# TM4C1237H6PGE register map
Vendor: Texas Instruments; Series: TM4C; File version: 12591
CPU: CM4 r1p2, little endian, MPU, FPU, 3 interrupt priority bits
Registers are 32-bit, read-write, no defined reset value unless marked. A register's access mark holds for its fields unless they carry their own. Offsets are from the block's base; [hi:lo] are bit positions; {n}, {i} and the like mark numbered series.

## HIB — Register map for HIB peripheral
Base 0x400FC000; register names take the prefix HIB
0x00 RTCC — Hibernation RTC Counter
  [31:0] HIB_RTCC — RTC Counter
0x04 RTCM0 — Hibernation RTC Match 0
  [31:0] HIB_RTCM0 — RTC Match 0
0x0C RTCLD — Hibernation RTC Load
  [31:0] HIB_RTCLD — RTC Load
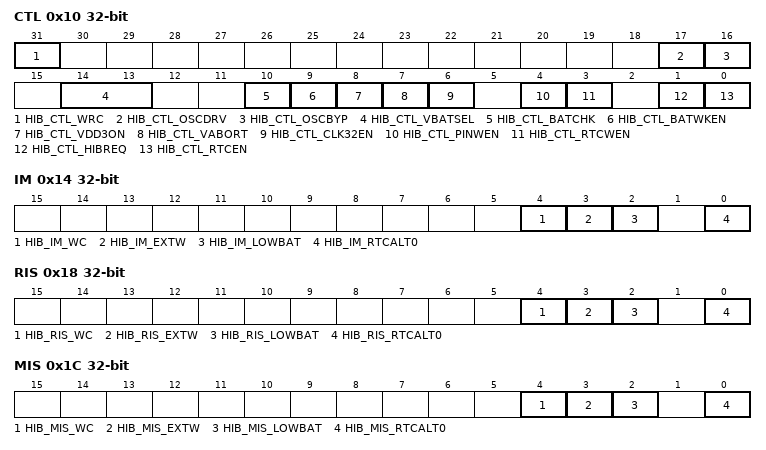
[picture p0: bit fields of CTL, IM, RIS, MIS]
0x10 CTL — Hibernation Control
  [31] HIB_CTL_WRC — Write Complete/Capable
  [17] HIB_CTL_OSCDRV — Oscillator Drive Capability
  [16] HIB_CTL_OSCBYP — Oscillator Bypass
  [14:13] HIB_CTL_VBATSEL — Select for Low-Battery Comparator
    0=HIB_CTL_VBATSEL_1_9V (1.9 Volts); 1=HIB_CTL_VBATSEL_2_1V (2.1 Volts (default)); 2=HIB_CTL_VBATSEL_2_3V (2.3 Volts); 3=HIB_CTL_VBATSEL_2_5V (2.5 Volts)
  [10] HIB_CTL_BATCHK — Check Battery Status
  [9] HIB_CTL_BATWKEN — Wake on Low Battery
  [8] HIB_CTL_VDD3ON — VDD Powered
  [7] HIB_CTL_VABORT — Power Cut Abort Enable
  [6] HIB_CTL_CLK32EN — Clocking Enable
  [4] HIB_CTL_PINWEN — External Wake Pin Enable
  [3] HIB_CTL_RTCWEN — RTC Wake-up Enable
  [1] HIB_CTL_HIBREQ — Hibernation Request
  [0] HIB_CTL_RTCEN — RTC Timer Enable
0x14 IM — Hibernation Interrupt Mask
  [4] HIB_IM_WC — External Write Complete/Capable Interrupt Mask
  [3] HIB_IM_EXTW — External Wake-Up Interrupt Mask
  [2] HIB_IM_LOWBAT — Low Battery Voltage Interrupt Mask
  [0] HIB_IM_RTCALT0 — RTC Alert 0 Interrupt Mask
0x18 RIS — Hibernation Raw Interrupt Status
  [4] HIB_RIS_WC — Write Complete/Capable Raw Interrupt Status
  [3] HIB_RIS_EXTW — External Wake-Up Raw Interrupt Status
  [2] HIB_RIS_LOWBAT — Low Battery Voltage Raw Interrupt Status
  [0] HIB_RIS_RTCALT0 — RTC Alert 0 Raw Interrupt Status
0x1C MIS — Hibernation Masked Interrupt Status
  [4] HIB_MIS_WC — Write Complete/Capable Masked Interrupt Status
  [3] HIB_MIS_EXTW — External Wake-Up Masked Interrupt Status
  [2] HIB_MIS_LOWBAT — Low Battery Voltage Masked Interrupt Status
  [0] HIB_MIS_RTCALT0 — RTC Alert 0 Masked Interrupt Status
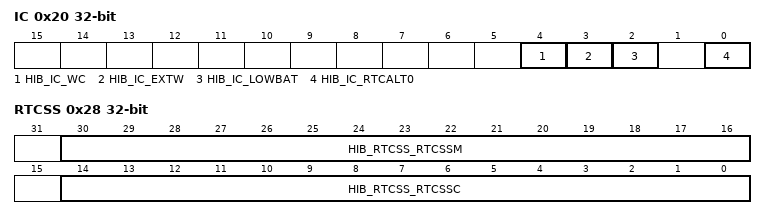
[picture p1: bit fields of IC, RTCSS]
0x20 IC — Hibernation Interrupt Clear
  [4] HIB_IC_WC — Write Complete/Capable Interrupt Clear
  [3] HIB_IC_EXTW — External Wake-Up Interrupt Clear
  [2] HIB_IC_LOWBAT — Low Battery Voltage Interrupt Clear
  [0] HIB_IC_RTCALT0 — RTC Alert0 Masked Interrupt Clear
0x24 RTCT — Hibernation RTC Trim
  [15:0] HIB_RTCT_TRIM — RTC Trim Value
0x28 RTCSS — Hibernation RTC Sub Seconds
  [30:16] HIB_RTCSS_RTCSSM — RTC Sub Seconds Match
  [14:0] HIB_RTCSS_RTCSSC — RTC Sub Seconds Count
0x30 DATA — Hibernation Data
  [31:0] HIB_DATA_RTD — Hibernation Module NV Data

## FLASH_CTRL — Register map for FLASH_CTRL peripheral
Base 0x400FD000; register names take the prefix FLASH_CTRL
0x00 FMA — Flash Memory Address
  [17:0] FLASH_FMA_OFFSET — Address Offset
0x04 FMD — Flash Memory Data
  [31:0] FLASH_FMD_DATA — Data Value
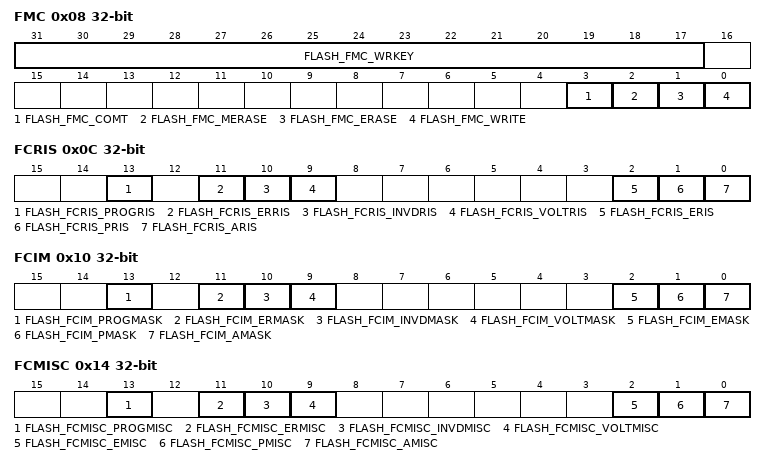
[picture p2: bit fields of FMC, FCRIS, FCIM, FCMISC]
0x08 FMC — Flash Memory Control
  [31:17] FLASH_FMC_WRKEY — FLASH write key
  [3] FLASH_FMC_COMT — Commit Register Value
  [2] FLASH_FMC_MERASE — Mass Erase Flash Memory
  [1] FLASH_FMC_ERASE — Erase a Page of Flash Memory
  [0] FLASH_FMC_WRITE — Write a Word into Flash Memory
0x0C FCRIS — Flash Controller Raw Interrupt Status
  [13] FLASH_FCRIS_PROGRIS — Program Verify Error Raw Interrupt Status
  [11] FLASH_FCRIS_ERRIS — Erase Verify Error Raw Interrupt Status
  [10] FLASH_FCRIS_INVDRIS — Invalid Data Raw Interrupt Status
  [9] FLASH_FCRIS_VOLTRIS — Pump Voltage Raw Interrupt Status
  [2] FLASH_FCRIS_ERIS — EEPROM Raw Interrupt Status
  [1] FLASH_FCRIS_PRIS — Programming Raw Interrupt Status
  [0] FLASH_FCRIS_ARIS — Access Raw Interrupt Status
0x10 FCIM — Flash Controller Interrupt Mask
  [13] FLASH_FCIM_PROGMASK — PROGVER Interrupt Mask
  [11] FLASH_FCIM_ERMASK — ERVER Interrupt Mask
  [10] FLASH_FCIM_INVDMASK — Invalid Data Interrupt Mask
  [9] FLASH_FCIM_VOLTMASK — VOLT Interrupt Mask
  [2] FLASH_FCIM_EMASK — EEPROM Interrupt Mask
  [1] FLASH_FCIM_PMASK — Programming Interrupt Mask
  [0] FLASH_FCIM_AMASK — Access Interrupt Mask
0x14 FCMISC — Flash Controller Masked Interrupt Status and Clear
  [13] FLASH_FCMISC_PROGMISC — PROGVER Masked Interrupt Status and Clear
  [11] FLASH_FCMISC_ERMISC — ERVER Masked Interrupt Status and Clear
  [10] FLASH_FCMISC_INVDMISC — Invalid Data Masked Interrupt Status and Clear
  [9] FLASH_FCMISC_VOLTMISC — VOLT Masked Interrupt Status and Clear
  [2] FLASH_FCMISC_EMISC — EEPROM Masked Interrupt Status and Clear
  [1] FLASH_FCMISC_PMISC — Programming Masked Interrupt Status and Clear
  [0] FLASH_FCMISC_AMISC — Access Masked Interrupt Status and Clear
0x20 FMC2 — Flash Memory Control 2
  [0] FLASH_FMC2_WRBUF — Buffered Flash Memory Write
0x30 FWBVAL — Flash Write Buffer Valid
  [31:0] FLASH_FWBVAL_FWB — Flash Memory Write Buffer
0x100 FWBN — Flash Write Buffer n
  [31:0] FLASH_FWBN_DATA — Data
0xFC0 FSIZE — Flash Size
  [15:0] FLASH_FSIZE_SIZE
    127=FLASH_FSIZE_SIZE_256KB (256 KB of Flash)
0xFC4 SSIZE — SRAM Size
  [15:0] FLASH_SSIZE_SIZE
    127=FLASH_SSIZE_SIZE_32KB (32 KB of SRAM)
0xFCC ROMSWMAP — ROM Software Map
0xFCC ROMSWMAP (FLASH_CTRL_ALT view) — ROM Software Map
  [0] FLASH_ROMSWMAP_SAFERTOS — SafeRTOS Present
0x10F0 RMCTL — ROM Control
  [0] FLASH_RMCTL_BA — Boot Alias
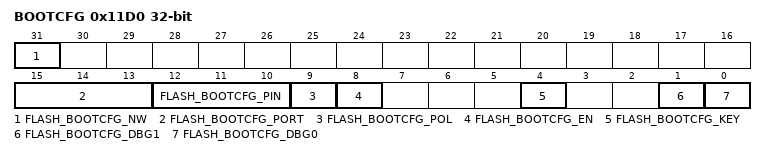
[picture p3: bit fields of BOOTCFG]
0x11D0 BOOTCFG — Boot Configuration
  [31] FLASH_BOOTCFG_NW — Not Written
  [15:13] FLASH_BOOTCFG_PORT — Boot GPIO Port
    0=FLASH_BOOTCFG_PORT_A (Port A); 1=FLASH_BOOTCFG_PORT_B (Port B); 2=FLASH_BOOTCFG_PORT_C (Port C); 3=FLASH_BOOTCFG_PORT_D (Port D); 4=FLASH_BOOTCFG_PORT_E (Port E); 5=FLASH_BOOTCFG_PORT_F (Port F); 6=FLASH_BOOTCFG_PORT_G (Port G); 7=FLASH_BOOTCFG_PORT_H (Port H)
  [12:10] FLASH_BOOTCFG_PIN — Boot GPIO Pin
    {v}=Pin {v} (v=0..7)
  [9] FLASH_BOOTCFG_POL — Boot GPIO Polarity
  [8] FLASH_BOOTCFG_EN — Boot GPIO Enable
  [4] FLASH_BOOTCFG_KEY — KEY Select
  [1] FLASH_BOOTCFG_DBG1 — Debug Control 1
  [0] FLASH_BOOTCFG_DBG0 — Debug Control 0
{0x11E0+4i} USERREG{i} (i=0..3) — User Register {i}
  [31:0] FLASH_USERREG{i}_DATA — User Data
{0x1200+4i} FMPRE{i} (i=0..3) — Flash Memory Protection Read Enable {i}
{0x1400+4i} FMPPE{i} (i=0..3) — Flash Memory Protection Program Enable {i}

## UDMA — Register map for UDMA peripheral
Base 0x400FF000; register names take the prefix UDMA
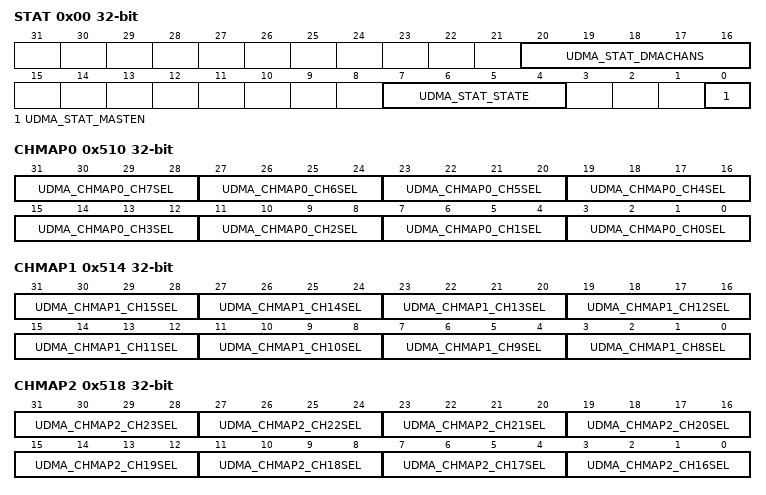
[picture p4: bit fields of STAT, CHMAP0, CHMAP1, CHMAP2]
0x00 STAT — DMA Status
  [20:16] UDMA_STAT_DMACHANS — Available uDMA Channels Minus 1
  [7:4] UDMA_STAT_STATE — Control State Machine Status
    0=UDMA_STAT_STATE_IDLE (Idle); 1=UDMA_STAT_STATE_RD_CTRL (Reading channel controller data); 2=UDMA_STAT_STATE_RD_SRCENDP (Reading source end pointer); 3=UDMA_STAT_STATE_RD_DSTENDP (Reading destination end pointer); 4=UDMA_STAT_STATE_RD_SRCDAT (Reading source data); 5=UDMA_STAT_STATE_WR_DSTDAT (Writing destination data); 6=UDMA_STAT_STATE_WAIT (Waiting for uDMA request to clear); 7=UDMA_STAT_STATE_WR_CTRL (Writing channel controller data); 8=UDMA_STAT_STATE_STALL (Stalled); 9=UDMA_STAT_STATE_DONE (Done); 10=UDMA_STAT_STATE_UNDEF (Undefined)
  [0] UDMA_STAT_MASTEN — Master Enable Status
0x04 CFG wo — DMA Configuration
  [0] UDMA_CFG_MASTEN — Controller Master Enable
0x08 CTLBASE — DMA Channel Control Base Pointer
  [31:10] UDMA_CTLBASE_ADDR — Channel Control Base Address
0x0C ALTBASE — DMA Alternate Channel Control Base Pointer
  [31:0] UDMA_ALTBASE_ADDR — Alternate Channel Address Pointer
0x10 WAITSTAT — DMA Channel Wait-on-Request Status
  [31:0] UDMA_WAITSTAT_WAITREQ — Channel [n] Wait Status
0x14 SWREQ wo — DMA Channel Software Request
  [31:0] UDMA_SWREQ — Channel [n] Software Request
0x18 USEBURSTSET — DMA Channel Useburst Set
  [31:0] UDMA_USEBURSTSET_SET — Channel [n] Useburst Set
0x1C USEBURSTCLR wo — DMA Channel Useburst Clear
  [31:0] UDMA_USEBURSTCLR_CLR — Channel [n] Useburst Clear
0x20 REQMASKSET — DMA Channel Request Mask Set
  [31:0] UDMA_REQMASKSET_SET — Channel [n] Request Mask Set
0x24 REQMASKCLR wo — DMA Channel Request Mask Clear
  [31:0] UDMA_REQMASKCLR_CLR — Channel [n] Request Mask Clear
0x28 ENASET — DMA Channel Enable Set
  [31:0] UDMA_ENASET_SET — Channel [n] Enable Set
0x2C ENACLR wo — DMA Channel Enable Clear
  [31:0] UDMA_ENACLR_CLR — Clear Channel [n] Enable Clear
0x30 ALTSET — DMA Channel Primary Alternate Set
  [31:0] UDMA_ALTSET_SET — Channel [n] Alternate Set
0x34 ALTCLR wo — DMA Channel Primary Alternate Clear
  [31:0] UDMA_ALTCLR_CLR — Channel [n] Alternate Clear
0x38 PRIOSET — DMA Channel Priority Set
  [31:0] UDMA_PRIOSET_SET — Channel [n] Priority Set
0x3C PRIOCLR wo — DMA Channel Priority Clear
  [31:0] UDMA_PRIOCLR_CLR — Channel [n] Priority Clear
0x4C ERRCLR — DMA Bus Error Clear
  [0] UDMA_ERRCLR_ERRCLR — uDMA Bus Error Status
0x500 CHASGN — DMA Channel Assignment
  [31:0] UDMA_CHASGN — Channel [n] Assignment Select
    0=UDMA_CHASGN_PRIMARY (Use the primary channel assignment); 1=UDMA_CHASGN_SECONDARY (Use the secondary channel assignment)
0x504 CHIS — DMA Channel Interrupt Status
  [31:0] UDMA_CHIS — Channel [n] Interrupt Status
0x510 CHMAP0 — DMA Channel Map Select 0
  [4n+3:4n] UDMA_CHMAP0_CH{n}SEL (n=0..7) — uDMA Channel {n} Source Select
0x514 CHMAP1 — DMA Channel Map Select 1
  [4n-29:4n-32] UDMA_CHMAP1_CH{n}SEL (n=8..15) — uDMA Channel {n} Source Select
0x518 CHMAP2 — DMA Channel Map Select 2
  [4n-61:4n-64] UDMA_CHMAP2_CH{n}SEL (n=16..23) — uDMA Channel {n} Source Select
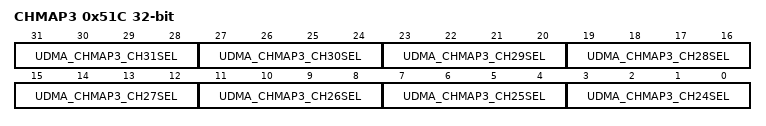
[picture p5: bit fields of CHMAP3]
0x51C CHMAP3 — DMA Channel Map Select 3
  [4n-93:4n-96] UDMA_CHMAP3_CH{n}SEL (n=24..31) — uDMA Channel {n} Source Select

## Notices in the file
Software License Agreement
Texas Instruments (TI) is supplying this software for use solely and
exclusively on TI's microcontroller products. The software is owned by
TI and/or its suppliers, and is protected under applicable copyright
laws. You may not combine this software with "viral" open-source
software in order to form a larger program.
THIS SOFTWARE IS PROVIDED "AS IS" AND WITH ALL FAULTS.
NO WARRANTIES, WHETHER EXPRESS, IMPLIED OR STATUTORY, INCLUDING, BUT
NOT LIMITED TO, IMPLIED WARRANTIES OF MERCHANTABILITY AND FITNESS FOR
A PARTICULAR PURPOSE APPLY TO THIS SOFTWARE. TI SHALL NOT, UNDER ANY
CIRCUMSTANCES, BE LIABLE FOR SPECIAL, INCIDENTAL, OR CONSEQUENTIAL
DAMAGES, FOR ANY REASON WHATSOEVER.
